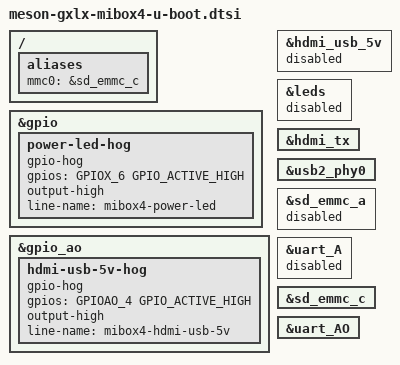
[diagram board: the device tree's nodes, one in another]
// SPDX-License-Identifier: (GPL-2.0+ OR MIT)

#include "meson-gxl-u-boot.dtsi"

/ {
	aliases {
		mmc0 = &sd_emmc_c;
		/delete-property/ mmc1;
		/delete-property/ mmc2;
	};
};

/* Xiaomi BL33 drives both lines high during normal startup. */
&gpio {
	power-led-hog {
		gpio-hog;
		gpios = <GPIOX_6 GPIO_ACTIVE_HIGH>;
		output-high;
		line-name = "mibox4-power-led";
	};
};

&gpio_ao {
	hdmi-usb-5v-hog {
		gpio-hog;
		gpios = <GPIOAO_4 GPIO_ACTIVE_HIGH>;
		output-high;
		line-name = "mibox4-hdmi-usb-5v";
	};
};

/* The hog owns these GPIOs in U-Boot; Linux uses the semantic devices. */
&hdmi_usb_5v {
	status = "disabled";
};

&leds {
	status = "disabled";
};

&hdmi_tx {
	/delete-property/ hdmi-supply;
};

&usb2_phy0 {
	/delete-property/ phy-supply;
};

/* U-Boot does not need to enumerate the soldered SDIO Wi-Fi function. */
&sd_emmc_a {
	status = "disabled";
};

/* Bluetooth UART and control GPIOs are initialized by Linux. */
&uart_A {
	status = "disabled";
};

&sd_emmc_c {
	bootph-all;
};

&uart_AO {
	bootph-all;
};
